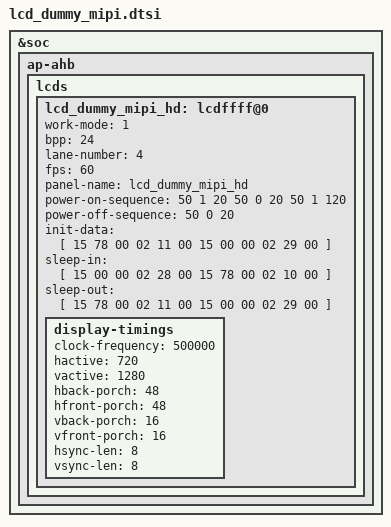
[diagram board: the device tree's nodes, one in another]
&soc { ap-ahb { lcds {
		lcd_dummy_mipi_hd: lcdffff@0 {

			work-mode = <1>;
			bpp = <24>;
			lane-number = <4>;

			fps = <60>;
			panel-name = "lcd_dummy_mipi_hd";

			power-on-sequence = <
						50  1  20
						50  0  20
						50  1  120
						>;
			power-off-sequence = <
						50  0  20
						>;

			init-data = [
				15 78 00 02 11 00
				15 00 00 02 29 00
				];
			sleep-in =  [
				15 00 00 02 28 00
				15 78 00 02 10 00
				];
			sleep-out = [
				15 78 00 02 11 00
				15 00 00 02 29 00
				];

			display-timings {
				clock-frequency = <500000>;
				hactive = <720>;
				vactive = <1280>;
				hback-porch = <48>;
				hfront-porch = <48>;
				vback-porch = <16>;
				vfront-porch = <16>;
				hsync-len = <8>;
				vsync-len = <8>;
			};
		};
}; }; };
